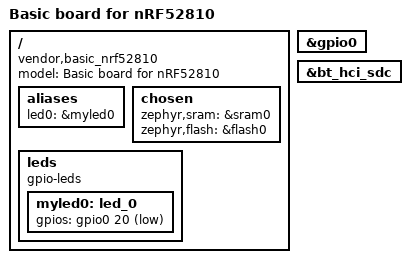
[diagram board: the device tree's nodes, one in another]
                                                                              /*
 * Copyright (c) 2021 Nordic Semiconductor ASA
 * SPDX-License-Identifier: Apache-2.0
 */

/dts-v1/;
#include <nordic/nrf52810_qfaa.dtsi>



/ {
	model = "Basic board for nRF52810";
	compatible = "vendor,basic_nrf52810";

	aliases {
		led0 = &myled0;
	};

	chosen {
		zephyr,sram = &sram0;
		zephyr,flash = &flash0;
	};

     leds {
            compatible = "gpio-leds";
            myled0: led_0 {
		         gpios = <&gpio0 20 GPIO_ACTIVE_LOW>;
             };
     };
};

&gpio0 {
	status = "okay";
};

&bt_hci_sdc {
	status = "okay";
};
